# STM32L471xx register map
File version: 1.0
Registers are 32-bit, access not given, reset 0x0 unless marked. A register's access mark holds for its fields unless they carry their own. Offsets are from the block's base; [hi:lo] are bit positions; {n}, {i} and the like mark numbered series; 'fields as' and 'values as' point back to an identical list.

## VREFBUF
Base 0x40010030
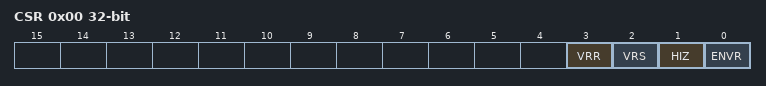
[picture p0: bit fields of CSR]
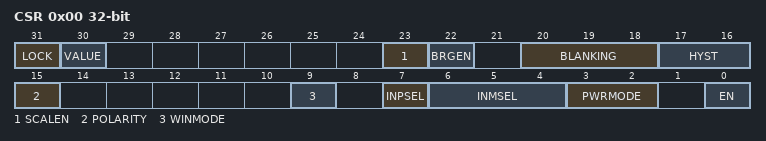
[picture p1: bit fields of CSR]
0x00 CSR
  [3] VRR, [2] VRS, [1] HIZ, [0] ENVR
0x04 CCR
  [5:0] TRIM

## COMP1
Base 0x40010200
Same registers: COMP2 0x40010204, COMP12_COMMON 0x40010204
0x00 CSR
  [31] LOCK, [30] VALUE, [23] SCALEN, [22] BRGEN, [20:18] BLANKING, [17:16] HYST, [15] POLARITY, [9] WINMODE, [7] INPSEL, [6:4] INMSEL, [3:2] PWRMODE, [0] EN

## EXTI
Base 0x40010400
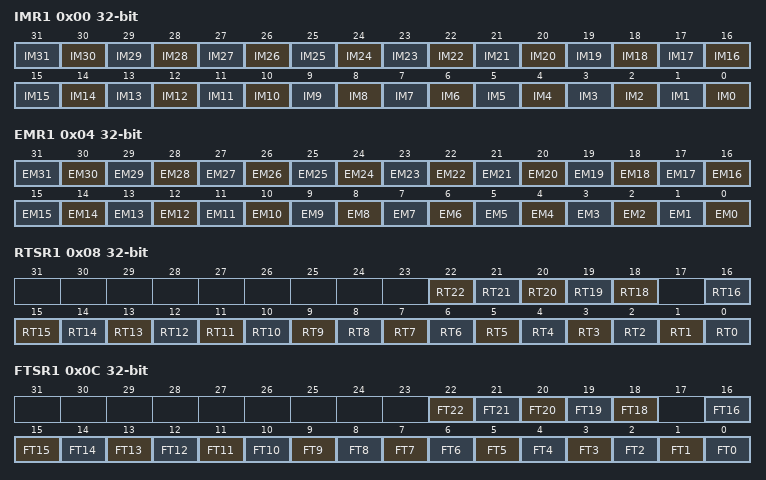
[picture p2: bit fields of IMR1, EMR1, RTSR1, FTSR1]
0x00 IMR1
  [n] IM{n} (n=0..31)
0x04 EMR1
  [n] EM{n} (n=0..31)
0x08 RTSR1
  [n] RT{n} (n=18..22), [n] RT{n} (n=0..16)
0x0C FTSR1
  [n] FT{n} (n=18..22), [n] FT{n} (n=0..16)
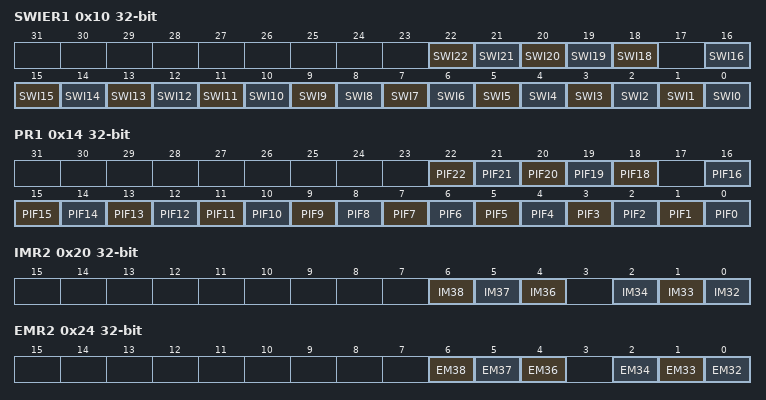
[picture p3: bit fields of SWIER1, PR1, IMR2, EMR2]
0x10 SWIER1
  [n] SWI{n} (n=18..22), [n] SWI{n} (n=0..16)
0x14 PR1
  [n] PIF{n} (n=18..22), [n] PIF{n} (n=0..16)
0x20 IMR2
  [6] IM38, [5] IM37, [4] IM36, [2] IM34, [1] IM33, [0] IM32
0x24 EMR2
  [6] EM38, [5] EM37, [4] EM36, [2] EM34, [1] EM33, [0] EM32
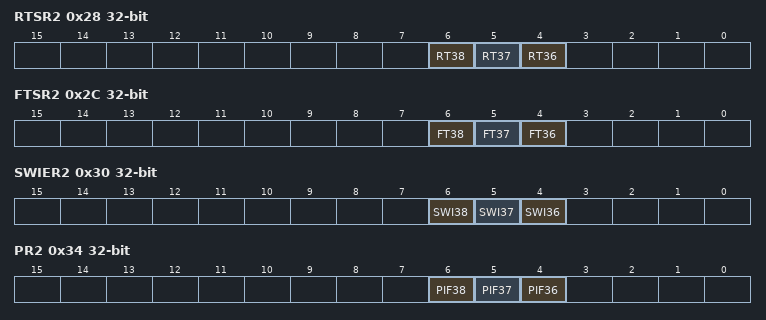
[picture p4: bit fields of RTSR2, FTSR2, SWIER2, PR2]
0x28 RTSR2
  [6] RT38, [5] RT37, [4] RT36
0x2C FTSR2
  [6] FT38, [5] FT37, [4] FT36
0x30 SWIER2
  [6] SWI38, [5] SWI37, [4] SWI36
0x34 PR2
  [6] PIF38, [5] PIF37, [4] PIF36

## FIREWALL
Base 0x40011C00
0x00 CSSA
0x04 CSL
0x08 NVDSSA
0x0C NVDSL
0x10 VDSSA
0x14 VDSL
0x20 CR

## SDMMC1
Base 0x40012800
0x00 POWER
  [1:0] PWRCTRL
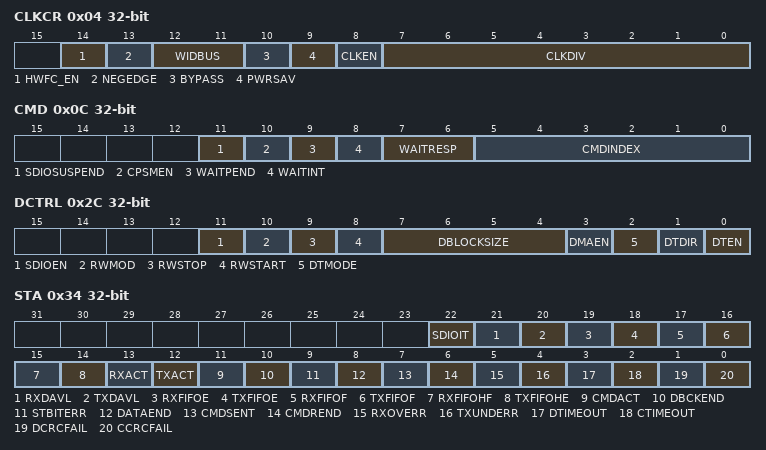
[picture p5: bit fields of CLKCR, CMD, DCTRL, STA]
0x04 CLKCR
  [14] HWFC_EN, [13] NEGEDGE, [12:11] WIDBUS, [10] BYPASS, [9] PWRSAV, [8] CLKEN, [7:0] CLKDIV
0x08 ARG
  [31:0] CMDARG
0x0C CMD
  [11] SDIOSUSPEND, [10] CPSMEN, [9] WAITPEND, [8] WAITINT, [7:6] WAITRESP, [5:0] CMDINDEX
0x10 RESPCMD
  [5:0] RESPCMD
{0x10+4i} RESP{i} (i=1..4)
  [31:0] CARDSTATUS{i}
0x24 DTIMER
  [31:0] DATATIME
0x28 DLEN
  [24:0] DATALENGTH
0x2C DCTRL
  [11] SDIOEN, [10] RWMOD, [9] RWSTOP, [8] RWSTART, [7:4] DBLOCKSIZE, [3] DMAEN, [2] DTMODE, [1] DTDIR, [0] DTEN
0x30 DCOUNT
  [24:0] DATACOUNT
0x34 STA
  [22] SDIOIT, [21] RXDAVL, [20] TXDAVL, [19] RXFIFOE, [18] TXFIFOE, [17] RXFIFOF, [16] TXFIFOF, [15] RXFIFOHF, [14] TXFIFOHE, [13] RXACT, [12] TXACT, [11] CMDACT, [10] DBCKEND, [9] STBITERR, [8] DATAEND, [7] CMDSENT, [6] CMDREND, [5] RXOVERR, [4] TXUNDERR, [3] DTIMEOUT, [2] CTIMEOUT, [1] DCRCFAIL, [0] CCRCFAIL
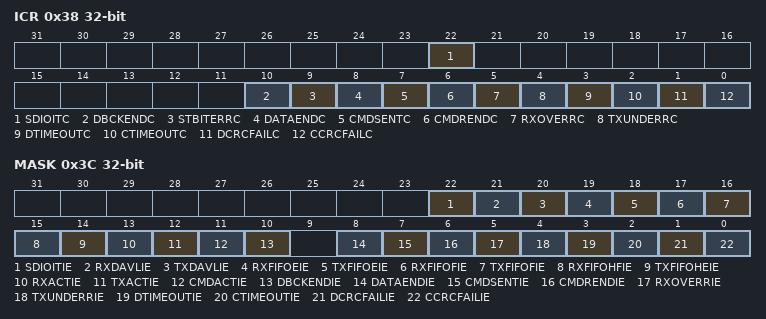
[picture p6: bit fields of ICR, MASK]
0x38 ICR
  [22] SDIOITC, [10] DBCKENDC, [9] STBITERRC, [8] DATAENDC, [7] CMDSENTC, [6] CMDRENDC, [5] RXOVERRC, [4] TXUNDERRC, [3] DTIMEOUTC, [2] CTIMEOUTC, [1] DCRCFAILC, [0] CCRCFAILC
0x3C MASK
  [22] SDIOITIE, [21] RXDAVLIE, [20] TXDAVLIE, [19] RXFIFOEIE, [18] TXFIFOEIE, [17] RXFIFOFIE, [16] TXFIFOFIE, [15] RXFIFOHFIE, [14] TXFIFOHEIE, [13] RXACTIE, [12] TXACTIE, [11] CMDACTIE, [10] DBCKENDIE, [8] DATAENDIE, [7] CMDSENTIE, [6] CMDRENDIE, [5] RXOVERRIE, [4] TXUNDERRIE, [3] DTIMEOUTIE, [2] CTIMEOUTIE, [1] DCRCFAILIE, [0] CCRCFAILIE
0x48 FIFOCNT
  [23:0] FIFOCOUNT
0x80 FIFO
  [31:0] FIFODATA

## SAI1
Base 0x40015400
Same registers: SAI2 0x40015800
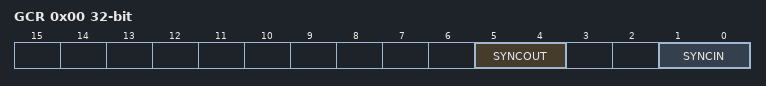
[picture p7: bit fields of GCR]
0x00 GCR
  [5:4] SYNCOUT, [1:0] SYNCIN
0x04 CR1A
0x08 CR2A
0x10 FRCRA
0x1C SLOTRA
0x24 CR1B
0x28 CR2B
0x2C IMRA
0x30 FRCRB
0x3C SLOTRB
0x40 SRA
0x4C IMRB
0x58 CLRFRA
0x60 SRB
0x74 DRA
0x78 CLRFRB
0x94 DRB

## DFSDM1
Base 0x40016000
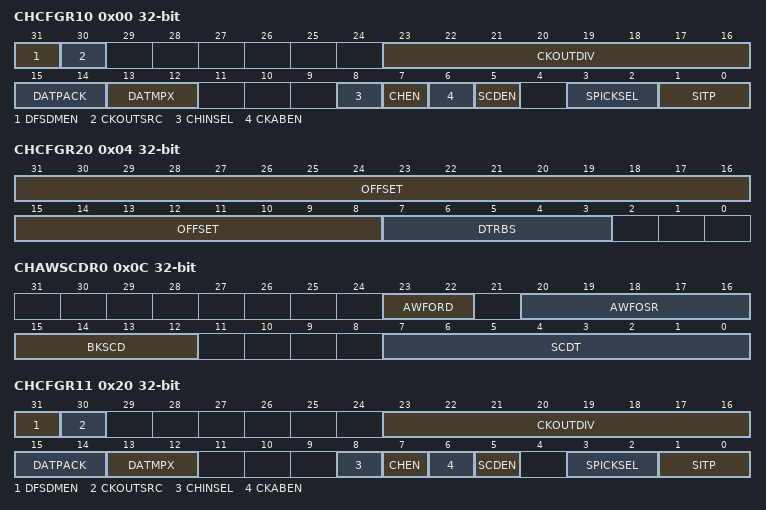
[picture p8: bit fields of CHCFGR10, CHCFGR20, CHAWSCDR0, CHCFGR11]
0x00 CHCFGR10
  [31] DFSDMEN, [30] CKOUTSRC, [23:16] CKOUTDIV, [15:14] DATPACK, [13:12] DATMPX, [8] CHINSEL, [7] CHEN, [6] CKABEN, [5] SCDEN, [3:2] SPICKSEL, [1:0] SITP
0x04 CHCFGR20
  [31:8] OFFSET, [7:3] DTRBS
0x0C CHAWSCDR0
  [23:22] AWFORD, [20:16] AWFOSR, [15:12] BKSCD, [7:0] SCDT
0x18 CHWDATAR0
0x20 CHCFGR11
  fields as CHCFGR10
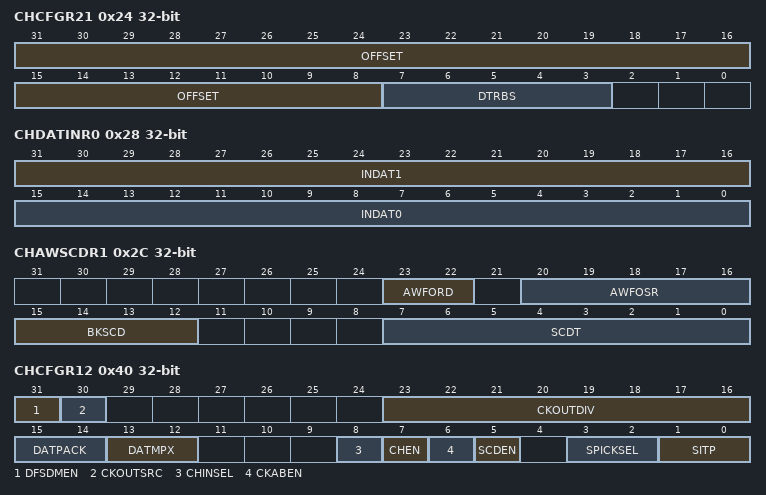
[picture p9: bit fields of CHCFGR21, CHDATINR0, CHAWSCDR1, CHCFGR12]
0x24 CHCFGR21
  [31:8] OFFSET, [7:3] DTRBS
0x28 CHDATINR0
  [31:16] INDAT1, [15:0] INDAT0
0x2C CHAWSCDR1
  [23:22] AWFORD, [20:16] AWFOSR, [15:12] BKSCD, [7:0] SCDT
0x38 CHWDATAR1
0x40 CHCFGR12
  fields as CHCFGR10
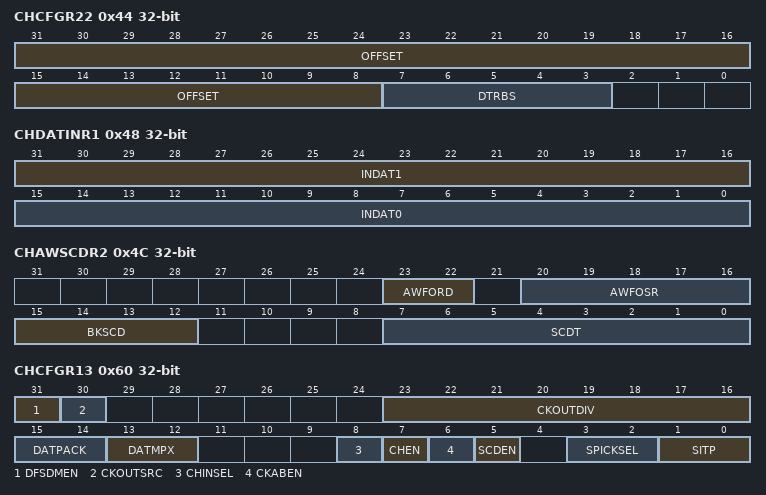
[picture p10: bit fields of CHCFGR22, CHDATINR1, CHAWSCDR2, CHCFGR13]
0x44 CHCFGR22
  [31:8] OFFSET, [7:3] DTRBS
0x48 CHDATINR1
  [31:16] INDAT1, [15:0] INDAT0
0x4C CHAWSCDR2
  [23:22] AWFORD, [20:16] AWFOSR, [15:12] BKSCD, [7:0] SCDT
0x58 CHWDATAR2
0x60 CHCFGR13
  fields as CHCFGR10
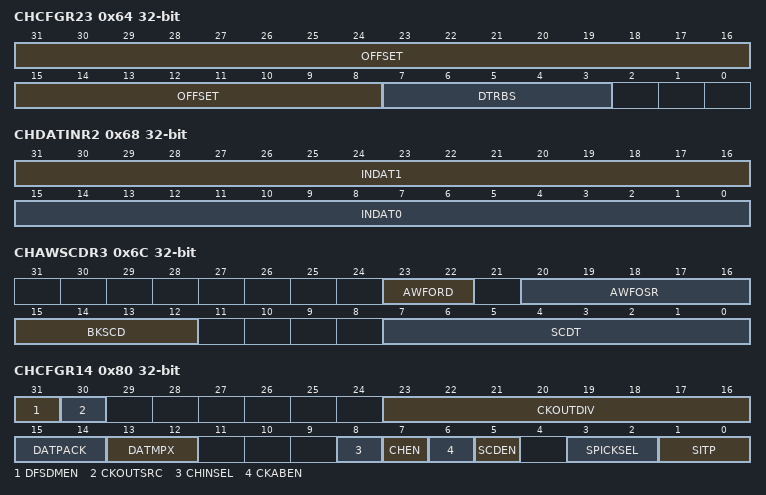
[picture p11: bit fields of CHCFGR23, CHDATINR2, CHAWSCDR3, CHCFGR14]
0x64 CHCFGR23
  [31:8] OFFSET, [7:3] DTRBS
0x68 CHDATINR2
  [31:16] INDAT1, [15:0] INDAT0
0x6C CHAWSCDR3
  [23:22] AWFORD, [20:16] AWFOSR, [15:12] BKSCD, [7:0] SCDT
0x78 CHWDATAR3
0x80 CHCFGR14
  fields as CHCFGR10
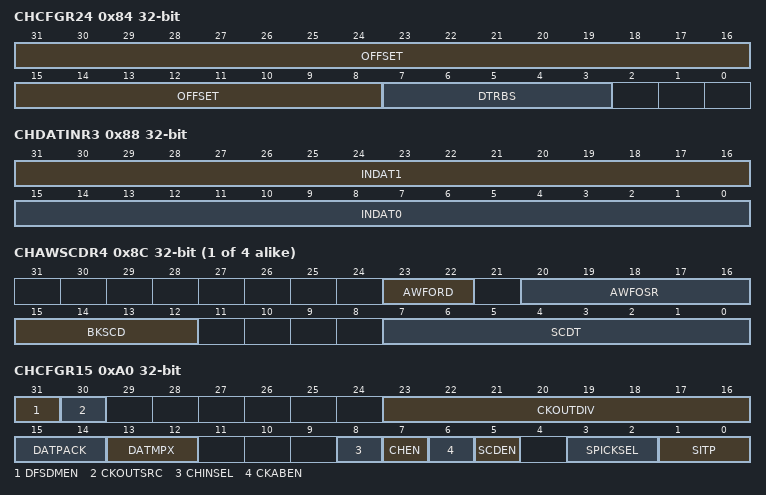
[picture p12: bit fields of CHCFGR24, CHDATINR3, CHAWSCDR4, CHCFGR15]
0x84 CHCFGR24
  [31:8] OFFSET, [7:3] DTRBS
0x88 CHDATINR3
  [31:16] INDAT1, [15:0] INDAT0
{0xC+0x20*i} CHAWSCDR{i} (i=4..7)
  [23:22] AWFORD, [20:16] AWFOSR, [15:12] BKSCD, [7:0] SCDT
{0x18+0x20*i} CHWDATAR{i} (i=4..7)
0xA0 CHCFGR15
  fields as CHCFGR10
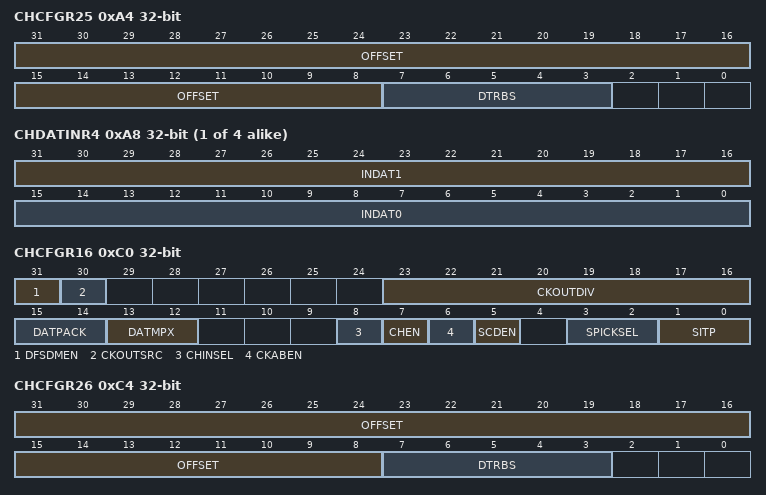
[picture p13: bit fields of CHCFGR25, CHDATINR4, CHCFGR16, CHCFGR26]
0xA4 CHCFGR25
  [31:8] OFFSET, [7:3] DTRBS
{0x28+0x20*i} CHDATINR{i} (i=4..7)
  [31:16] INDAT1, [15:0] INDAT0
0xC0 CHCFGR16
  fields as CHCFGR10
0xC4 CHCFGR26
  [31:8] OFFSET, [7:3] DTRBS
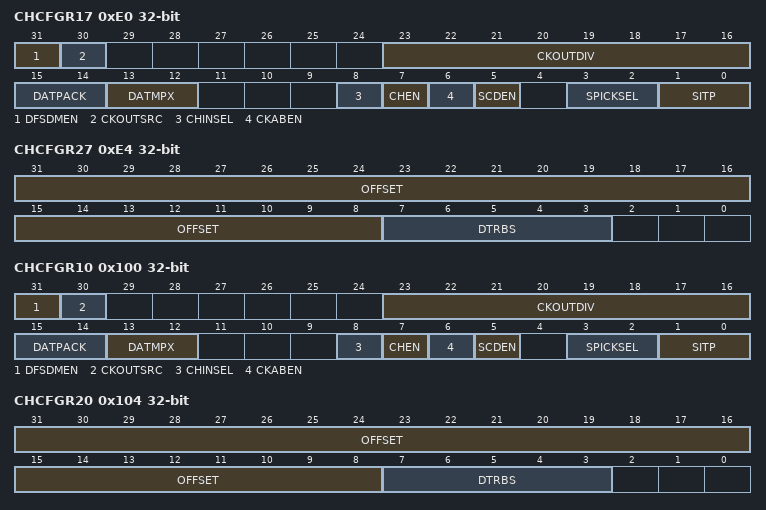
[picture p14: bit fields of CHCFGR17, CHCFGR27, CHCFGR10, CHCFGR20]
0xE0 CHCFGR17
  fields as CHCFGR10
0xE4 CHCFGR27
  [31:8] OFFSET, [7:3] DTRBS
0x100 CHCFGR10
  fields as CHCFGR10
0x104 CHCFGR20
  [31:8] OFFSET, [7:3] DTRBS
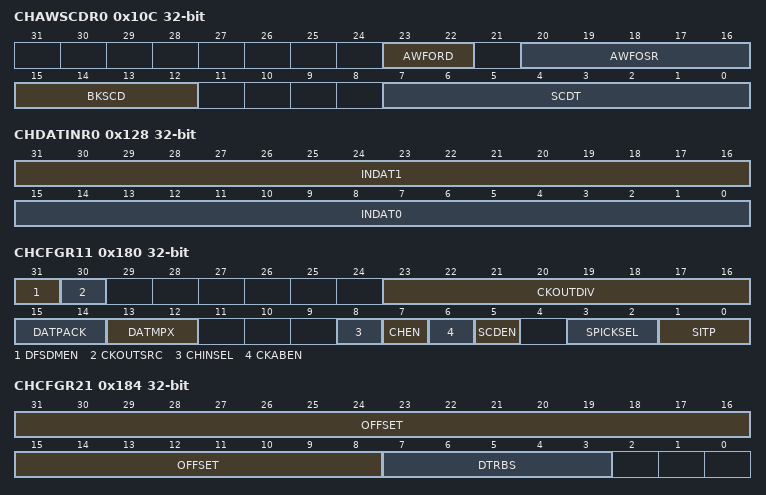
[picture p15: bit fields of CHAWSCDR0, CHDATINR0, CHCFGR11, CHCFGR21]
0x10C CHAWSCDR0
  [23:22] AWFORD, [20:16] AWFOSR, [15:12] BKSCD, [7:0] SCDT
0x118 CHWDATAR0
0x128 CHDATINR0
  [31:16] INDAT1, [15:0] INDAT0
0x180 CHCFGR11
  fields as CHCFGR10
0x184 CHCFGR21
  [31:8] OFFSET, [7:3] DTRBS
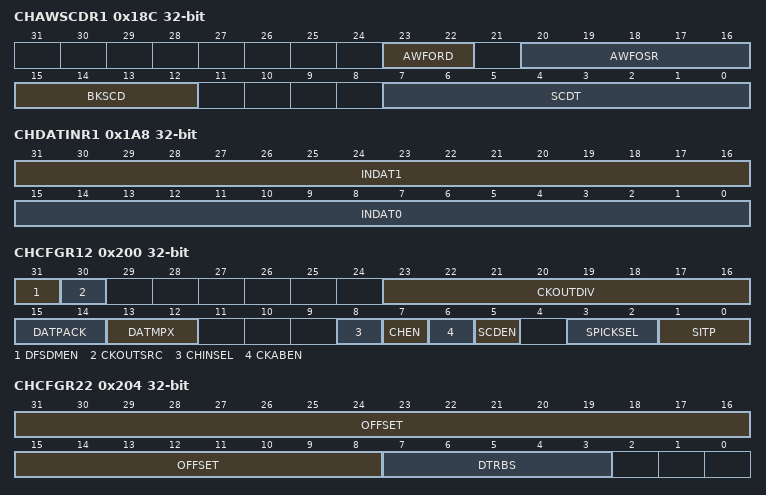
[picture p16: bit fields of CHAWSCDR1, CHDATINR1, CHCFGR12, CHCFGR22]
0x18C CHAWSCDR1
  [23:22] AWFORD, [20:16] AWFOSR, [15:12] BKSCD, [7:0] SCDT
0x198 CHWDATAR1
0x1A8 CHDATINR1
  [31:16] INDAT1, [15:0] INDAT0
0x200 CHCFGR12
  fields as CHCFGR10
0x204 CHCFGR22
  [31:8] OFFSET, [7:3] DTRBS
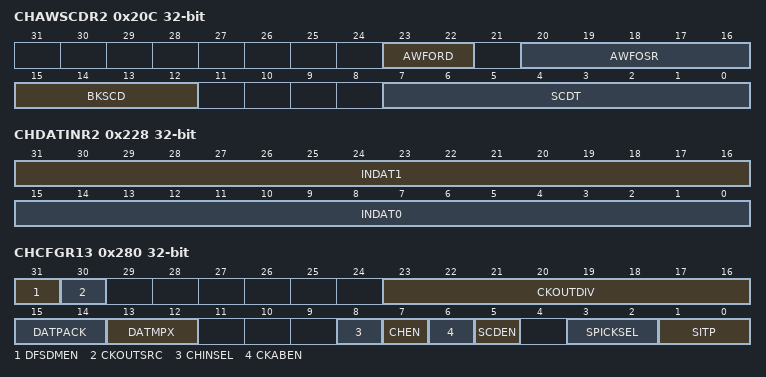
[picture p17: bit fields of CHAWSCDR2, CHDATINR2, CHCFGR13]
0x20C CHAWSCDR2
  [23:22] AWFORD, [20:16] AWFOSR, [15:12] BKSCD, [7:0] SCDT
0x218 CHWDATAR2
0x228 CHDATINR2
  [31:16] INDAT1, [15:0] INDAT0
0x280 CHCFGR13
  fields as CHCFGR10
0x284 CHCFGR23
  [31:8] OFFSET, [7:3] DTRBS
0x28C CHAWSCDR3
  [23:22] AWFORD, [20:16] AWFOSR, [15:12] BKSCD, [7:0] SCDT
0x298 CHWDATAR3
0x2A8 CHDATINR3
  [31:16] INDAT1, [15:0] INDAT0
